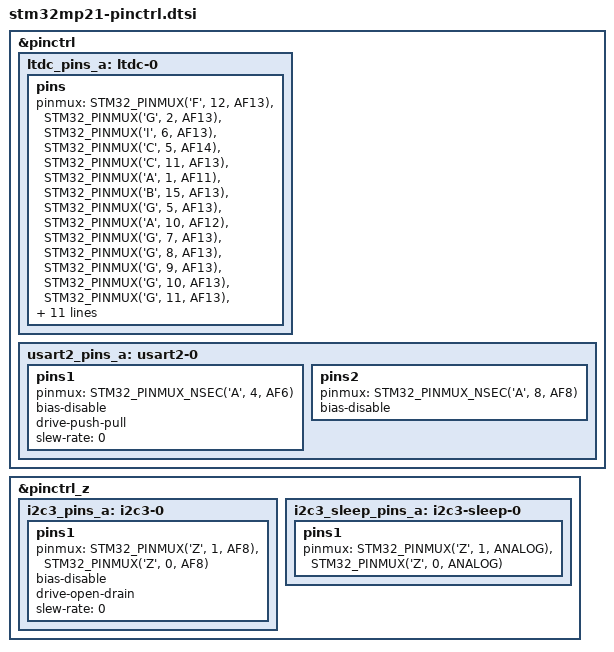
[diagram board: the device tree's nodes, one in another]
// SPDX-License-Identifier: (GPL-2.0-only OR BSD-3-Clause)
/*
 * Copyright (C) 2024, STMicroelectronics - All Rights Reserved
 * Author: Alexandre Torgue <alexandre.torgue@foss.st.com> for STMicroelectronics.
 */

#include <dt-bindings/pinctrl/stm32-pinfunc.h>

&pinctrl {
	ltdc_pins_a: ltdc-0 {
		pins {
			pinmux = <STM32_PINMUX('F', 12, AF13)>, /* LCD_CLK */
				 <STM32_PINMUX('G',  2, AF13)>, /* LCD_HSYNC */
				 <STM32_PINMUX('I',  6, AF13)>, /* LCD_VSYNC */
				 <STM32_PINMUX('C',  5, AF14)>, /* LCD_DE */
				 <STM32_PINMUX('C', 11, AF13)>, /* LCD_R2 */
				 <STM32_PINMUX('A',  1, AF11)>, /* LCD_R3 */
				 <STM32_PINMUX('B', 15, AF13)>, /* LCD_R4 */
				 <STM32_PINMUX('G',  5, AF13)>, /* LCD_R5 */
				 <STM32_PINMUX('A', 10, AF12)>, /* LCD_R6 */
				 <STM32_PINMUX('G',  7, AF13)>, /* LCD_R7 */
				 <STM32_PINMUX('G',  8, AF13)>, /* LCD_G2 */
				 <STM32_PINMUX('G',  9, AF13)>, /* LCD_G3 */
				 <STM32_PINMUX('G', 10, AF13)>, /* LCD_G4 */
				 <STM32_PINMUX('G', 11, AF13)>, /* LCD_G5 */
				 <STM32_PINMUX('G', 12, AF13)>, /* LCD_G6 */
				 <STM32_PINMUX('C',  0, AF13)>, /* LCD_G7 */
				 <STM32_PINMUX('G', 15, AF13)>, /* LCD_B2 */
				 <STM32_PINMUX('I',  0, AF13)>, /* LCD_B3 */
				 <STM32_PINMUX('I',  1, AF13)>, /* LCD_B4 */
				 <STM32_PINMUX('A',  7, AF10)>, /* LCD_B5 */
				 <STM32_PINMUX('F',  5, AF13)>, /* LCD_B6 */
				 <STM32_PINMUX('I',  4, AF13)>; /* LCD_B7 */
			bias-disable;
			drive-push-pull;
			slew-rate = <0>;
		};
	};

	usart2_pins_a: usart2-0 {
		pins1 {
			pinmux = <STM32_PINMUX_NSEC('A', 4, AF6)>; /* USART2_TX */
			bias-disable;
			drive-push-pull;
			slew-rate = <0>;
		};
		pins2 {
			pinmux = <STM32_PINMUX_NSEC('A', 8, AF8)>; /* USART2_RX */
			bias-disable;
		};
	};
};

&pinctrl_z {
	i2c3_pins_a: i2c3-0 {
		pins1 {
			pinmux = <STM32_PINMUX('Z', 1, AF8)>, /* I2C3_SCL */
				 <STM32_PINMUX('Z', 0, AF8)>; /* I2C3_SDA */
			bias-disable;
			drive-open-drain;
			slew-rate = <0>;
		};
	};

	i2c3_sleep_pins_a: i2c3-sleep-0 {
		pins1 {
			pinmux = <STM32_PINMUX('Z', 1, ANALOG)>, /* I2C3_SCL */
				 <STM32_PINMUX('Z', 0, ANALOG)>; /* I2C3_SDA */
		};
	};
};
